VERSION "HIPBNYYYYYYYYYYYYYYYYYYYYYYYYYYYYYYYYYYYYY/4/%%%/4/'%**4YYY///"

NS_ :

BS_:

BU_:

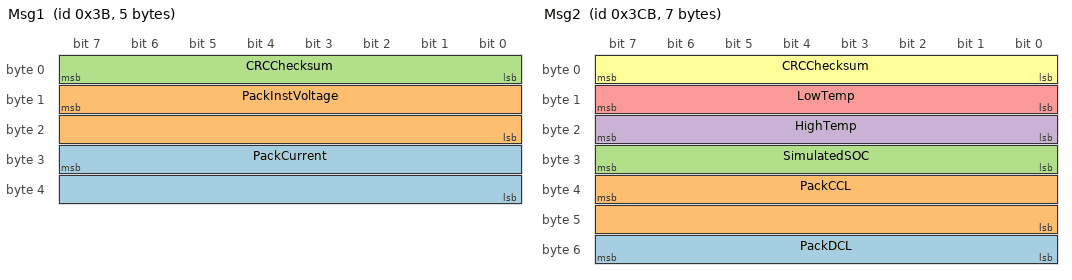
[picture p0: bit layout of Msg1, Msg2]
BO_ 59 Msg1: 5 Vector__XXX
 SG_ PackCurrent : 31|16@0+ (1,0) [0|0] "" Vector__XXX
 SG_ PackInstVoltage : 15|16@0+ (0.1,0) [0|0] "" Vector__XXX
 SG_ CRCChecksum : 7|8@0+ (1,64) [0|0] "" Vector__XXX

BO_ 971 Msg2: 7 Vector__XXX
 SG_ PackDCL : 55|8@0+ (1,0) [0|0] "" Vector__XXX
 SG_ PackCCL : 39|16@0+ (1,0) [0|0] "" Vector__XXX
 SG_ SimulatedSOC : 31|8@0+ (1,0) [0|0] "" Vector__XXX
 SG_ HighTemp : 23|8@0+ (1,0) [0|0] "" Vector__XXX
 SG_ LowTemp : 15|8@0+ (1,0) [0|0] "" Vector__XXX
 SG_ CRCChecksum : 7|8@0+ (1,981) [0|0] "" Vector__XXX

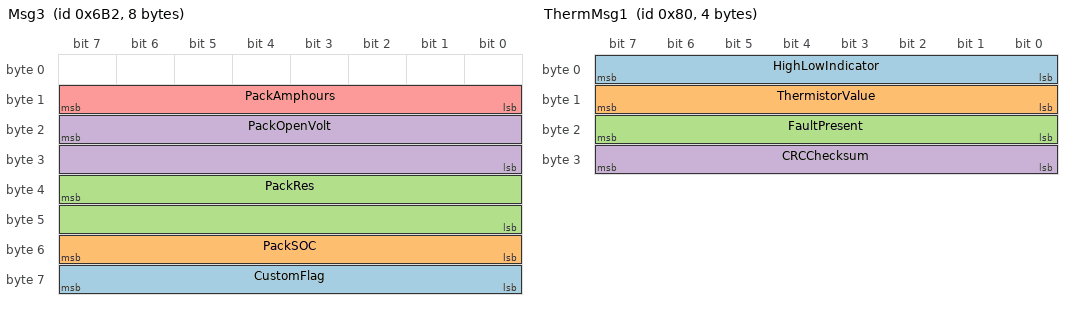
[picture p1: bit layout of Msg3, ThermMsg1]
BO_ 1714 Msg3: 8 Vector__XXX
 SG_ CustomFlag : 63|8@0+ (1,0) [0|0] "" Vector__XXX
 SG_ PackSOC : 55|8@0+ (0.5,0) [0|0] "" Vector__XXX
 SG_ PackRes : 39|16@0+ (1,0) [0|0] "" Vector__XXX
 SG_ PackOpenVolt : 23|16@0+ (0.1,0) [0|0] "" Vector__XXX
 SG_ PackAmphours : 15|8@0+ (0.05,0) [0|0] "" Vector__XXX

BO_ 128 ThermMsg1: 4 Vector__XXX
 SG_ HighLowIndicator : 7|8@0+ (1,0) [0|0] "" Vector__XXX
 SG_ ThermistorValue : 15|8@0- (1,0) [0|0] "" Vector__XXX
 SG_ FaultPresent : 23|8@0+ (1,0) [0|0] "" Vector__XXX
 SG_ CRCChecksum : 31|8@0+ (1,0) [0|0] "" Vector__XXX
